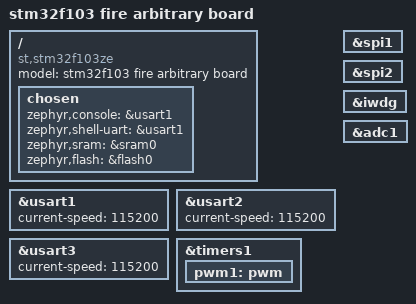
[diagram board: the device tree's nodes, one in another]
/*
 * Copyright (c) 2017 Linaro Limited
 *
 * SPDX-License-Identifier: Apache-2.0
 */

/dts-v1/;
#include <st/f1/stm32f103Xe.dtsi>

/ {
	model = "stm32f103 fire arbitrary board";
	compatible = "st,stm32f103ze";

	chosen {
		zephyr,console = &usart1;
		zephyr,shell-uart = &usart1;
		zephyr,sram = &sram0;
		zephyr,flash = &flash0;
	};
};

&usart1 {
	status = "okay";
	current-speed = <115200>;
};

&usart2 {
	current-speed = <115200>;
	status = "okay";
};

&usart3 {
	current-speed = <115200>;
};

&spi1 {
	status = "okay";
};

&spi2 {
	status = "okay";
};

&timers1 {
	status = "okay";

	pwm1: pwm {
		status = "okay";
	};
};

&iwdg {
	status = "okay";
};

&adc1 {
	status = "okay";
};
